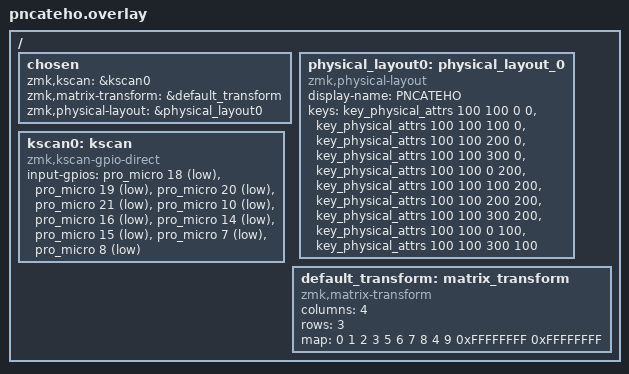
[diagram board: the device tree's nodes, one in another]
#include <dt-bindings/zmk/matrix_transform.h>
#include <physical_layouts.dtsi>

/ {
    chosen {
        zmk,kscan = &kscan0;
        zmk,matrix-transform = &default_transform;
        zmk,physical-layout = &physical_layout0;
    };

    physical_layout0: physical_layout_0 {
        compatible = "zmk,physical-layout";
        display-name = "PNCATEHO";
        // Порядок ключей строго соответствует map из matrix_transform
        keys  //            w    h    x     y
            = <&key_physical_attrs 100 100    0    0>   // 0 (LSHIFT)
            , <&key_physical_attrs 100 100  100    0>   // 1 (P)
            , <&key_physical_attrs 100 100  200    0>   // 2 (A)
            , <&key_physical_attrs 100 100  300    0>   // 3 (S)
            , <&key_physical_attrs 100 100    0  200>   // 5 (V)
            , <&key_physical_attrs 100 100  100  200>   // 6 (Z)
            , <&key_physical_attrs 100 100  200  200>   // 7 (LALT)
            , <&key_physical_attrs 100 100  300  200>   // 8 (SPACE)
            , <&key_physical_attrs 100 100    0  100>   // 4 (MO2)
            , <&key_physical_attrs 100 100  300  100>   // 9 (MO1)
            ;
    };

    kscan0: kscan {
        compatible = "zmk,kscan-gpio-direct";
        input-gpios
            = <&pro_micro 18 (GPIO_ACTIVE_LOW | GPIO_PULL_UP)>
            , <&pro_micro 19 (GPIO_ACTIVE_LOW | GPIO_PULL_UP)>
            , <&pro_micro 20 (GPIO_ACTIVE_LOW | GPIO_PULL_UP)>
            , <&pro_micro 21 (GPIO_ACTIVE_LOW | GPIO_PULL_UP)>
            , <&pro_micro 10 (GPIO_ACTIVE_LOW | GPIO_PULL_UP)>
            , <&pro_micro 16 (GPIO_ACTIVE_LOW | GPIO_PULL_UP)>
            , <&pro_micro 14 (GPIO_ACTIVE_LOW | GPIO_PULL_UP)>
            , <&pro_micro 15 (GPIO_ACTIVE_LOW | GPIO_PULL_UP)>
            , <&pro_micro 7  (GPIO_ACTIVE_LOW | GPIO_PULL_UP)>
            , <&pro_micro 8  (GPIO_ACTIVE_LOW | GPIO_PULL_UP)>
            ;
    };

    default_transform: matrix_transform {
        compatible = "zmk,matrix-transform";
        columns = <4>;
        rows = <3>;
        // Физические позиции (индексы) в порядке: 0,1,2,3,5,6,7,8,4,9
        map = <
            0 1 2 3
            5 6 7 8
            4 9 0xFFFFFFFF 0xFFFFFFFF
        >;
    };
};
